# allwinner_xr806_unofficial register map
File version: 1.2
CPU: CM33 r1p2, little endian, MPU, FPU, DSP, vendor SysTick, 8 interrupt priority bits, 8 SAU regions
Registers are 32-bit, read-write, reset 0x0 unless marked. A register's access mark holds for its fields unless they carry their own. Offsets are from the block's base; [hi:lo] are bit positions.

## UART0
Base 0x40040C00
Same registers: UART1 0x40041000, UART2 0x40041400
0x00 RBR ro — UART Receive Buffer Register
  [7:0] rbr
0x00 THR wo — UART Transmit Holding Register
  [7:0] thr
0x00 DLL — UART Divisor Latch Low Register
  [7:0] dll
0x04 DLH — UART Divisor Latch High Register
  [7:0] dlh
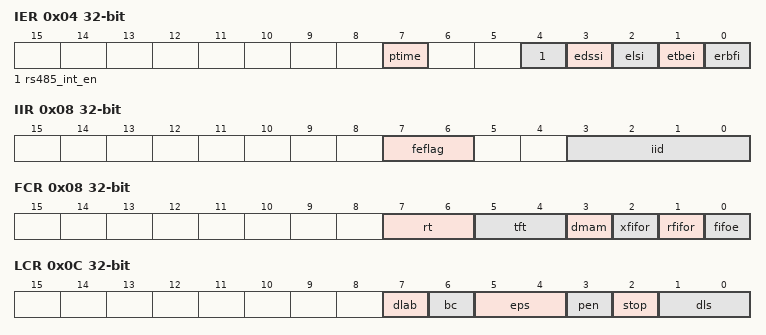
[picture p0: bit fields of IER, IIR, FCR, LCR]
0x04 IER — UART Interrupt Enable Register
  [all] fields
    0=disable; 1=enable
  [7] ptime — Programmable THRE Interrupt Mode Enable
  [4] rs485_int_en — RS485 Interrupt Enable
  [3] edssi — Enable Modem Status Interrupt
  [2] elsi — Enable Receiver Line Status Interrupt
  [1] etbei — Enable Transmit Holding Register Empty Interrupt
  [0] erbfi — Enable Received Data Available Interrupt
0x08 IIR ro — UART Interrupt Identity Register
  [7:6] feflag — FIFOs Enable Flag
    0=disable; 3=enable
  [3:0] iid — Interrupt ID
    0=modem_status; 1=no_interrupt_pending; 2=thr_empty; 3=rs485_interrupt; 4=received_data_available; 6=receiver_line_status; 7=busy_detect; 12=character_timeout
0x08 FCR wo — UART FIFO Control Register
  [7:6] rt
    0=one_character; 1=quarter_full; 2=half_full; 3=two_less_than_full
  [5:4] tft
    0=empty; 1=two_characters; 2=quarter_full; 3=half_full
  [3] dmam
    0=mode_0; 1=mode_1
  [2] xfifor
  [1] rfifor
  [0] fifoe
0x0C LCR — UART Line Control Register
  [7] dlab — Divisor Latch Access Bit
    0=rx_buffer; 1=divisor_latch
  [6] bc — Break Control Bit
  [5:4] eps — Even Parity Select
    0=odd; 1=even; 2=rs485_data; 3=rs485_addr
  [3] pen — Parity Enable
    0=disabled; 1=enabled
  [2] stop — Number of stop bits
    0=one (1 stop bit); 1=two (1.5 stop bits when DLS(LCR[1:0]) is zero, else 2 stop bits)
  [1:0] dls — Data Length Select
    0=five (5 bits); 1=six (6 bits); 2=seven (7 bits); 3=eight (8 bits)
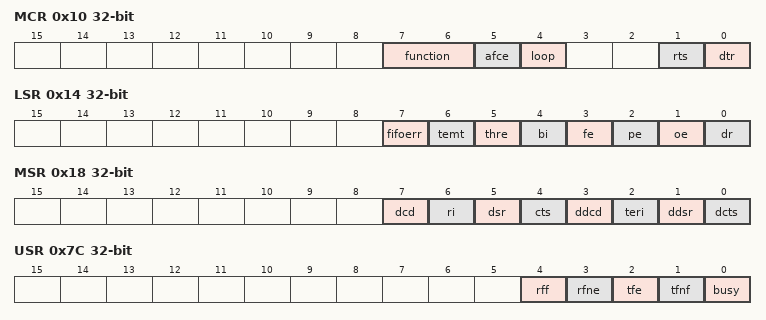
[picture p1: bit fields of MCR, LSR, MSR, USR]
0x10 MCR — UART Modem Control Register
  [7:6] function — UART Function: Select IrDA or RS485
    0=UART; 1=IrDA_SIR; 2=RS485
  [5] afce — Auto Flow Control Enable
    0=disabled; 1=enabled
  [4] loop — Loop Back Mode
    0=normal; 1=loop_back
  [1] rts — Request to Send
    0=deasserted; 1=asserted
  [0] dtr — Data Terminal Ready
    0=deasserted; 1=asserted
0x14 LSR ro — UART Line Status Register
  [7] fifoerr — RX Data Error in FIFO
    1=error
  [6] temt — Transmitter Empty
    1=empty
  [5] thre — TX Holding Register Empty
    1=empty
  [4] bi — Break Interrupt
  [3] fe — Framing Error
    1=error
  [2] pe — Parity Error
    1=error
  [1] oe — Overrun Error
    1=error
  [0] dr — Data Ready
    1=ready
0x18 MSR ro — UART Modem Status Register
  [7] dcd — Line State of Data Carrier Detect
    0=deasserted; 1=asserted
  [6] ri — Line State of Ring Indicator
    0=deasserted; 1=asserted
  [5] dsr — Line State of Data Set Ready
    0=deasserted; 1=asserted
  [4] cts — Line State of Clear To Send
    0=deasserted; 1=asserted
  [3] ddcd — Delta Data Carrier Detect
    0=no_change; 1=change
  [2] teri — Trailing Edge Ring Indicator
    0=no_change; 1=change
  [1] ddsr — Delta Data Set Ready
    0=no_change; 1=change
  [0] dcts — Delta Clear to Send
    0=no_change; 1=change
0x1C SCH — UART Scratch Register
  [7:0] scratch
0x7C USR ro — UART Status Register
  [4] rff — RX FIFO Full
    0=not_full; 1=full
  [3] rfne — RX FIFO Not Empty
    0=empty; 1=not_empty
  [2] tfe — TX FIFO Empty
    0=not_empty; 1=empty
  [1] tfnf — TX FIFO Not Full
    0=full; 1=not_full
  [0] busy — UART Busy Bit
    0=idle; 1=busy
0x80 TFL ro — UART Transmit FIFO Level Register
  [6:0] tfl — TX FIFO Level
0x84 RFL ro — UART Receive FIFO Level Register
  [6:0] rfl — RX FIFO Level
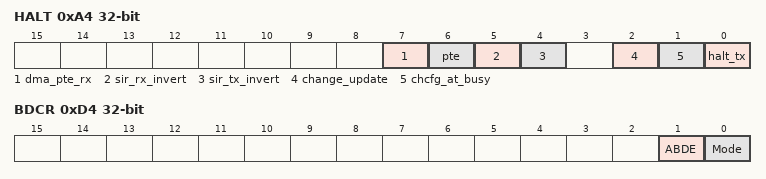
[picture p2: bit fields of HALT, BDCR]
0xA4 HALT — UART Halt TX Register
  [7] dma_pte_rx — The Transmission of RX_DRQ
  [6] pte — The sending of TX_REQ
  [5] sir_rx_invert — SIR RX Pulse Polarity Invert
    0=not_invert; 1=invert
  [4] sir_tx_invert — SIR TX Pulse Polarity Invert
    0=not_invert; 1=invert
  [2] change_update
    0=finished; 1=update_trigger
  [1] chcfg_at_busy
    0=disable; 1=enable
  [0] halt_tx
    0=disabled; 1=enabled
0xB0 DBG_DLL ro — UART Debug DLL Register
  [7:0] DBG_DLL
0xB4 DBG_DLH ro — UART Debug DLH Register
  [7:0] DBG_DLH
0xC0 RS485_CTL — UART RS485 Control and Status Register
0xC4 RS485_ADDR_MATCH — UART RS485 Address Match Register
0xC8 RS485_BUS_IDLE_CHK — UART RS485 Bus Idle Check Register
0xCC TX_DLY — UART TX Delay Register
  [7:0] DLY
0xD4 BDCR — UART Baudrate Detection Control Register
  [1] ABDE — Auto Baudrate Detect Enable
    0=disable; 1=enable
  [0] Mode
    0=compare; 1=normal
0xD8 BDCLR — UART Baudrate Detection Counter Low Register
  [7:0] BDCL
0xDC BDCHR — UART Baudrate Detection Counter High Register
  [7:0] BDCH
